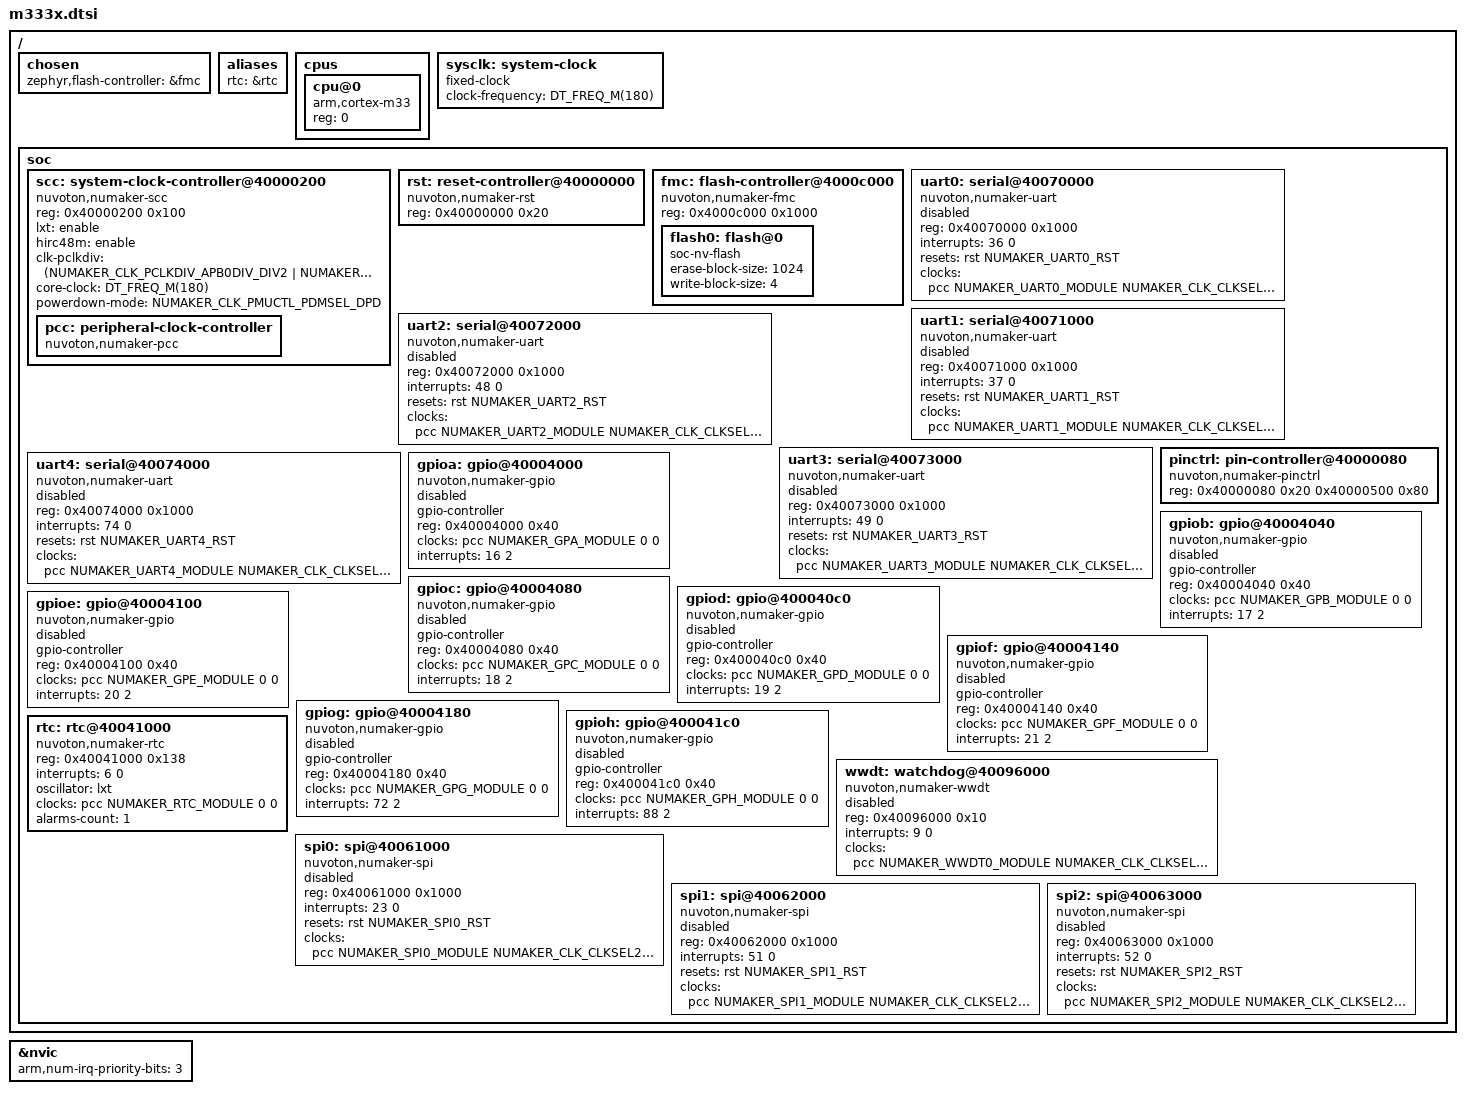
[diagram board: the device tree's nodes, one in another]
/*
 * Copyright (c) 2025 Nuvoton Technology Corporation.
 *
 * SPDX-License-Identifier: Apache-2.0
 */

#include <arm/armv8-m.dtsi>
#include <mem.h>
#include <freq.h>
#include <zephyr/dt-bindings/clock/numaker_m333x_clock.h>
#include <zephyr/dt-bindings/reset/numaker_m333x_reset.h>
#include <zephyr/dt-bindings/gpio/gpio.h>

/ {
	chosen {
		zephyr,flash-controller = &fmc;
	};

	aliases {
		rtc = &rtc;
	};

	cpus {
		#address-cells = <1>;
		#size-cells = <0>;

		cpu@0 {
			device_type = "cpu";
			compatible = "arm,cortex-m33";
			reg = <0>;
		};
	};

	sysclk: system-clock {
		compatible = "fixed-clock";
		clock-frequency = <DT_FREQ_M(180)>;
		#clock-cells = <0>;
	};

	soc {
		scc: system-clock-controller@40000200 {
			compatible = "nuvoton,numaker-scc";
			reg = <0x40000200 0x100>;
			#clock-cells = <0>;
			lxt = "enable";
			hirc48m = "enable";
			clk-pclkdiv = <(NUMAKER_CLK_PCLKDIV_APB0DIV_DIV2 |
				       NUMAKER_CLK_PCLKDIV_APB1DIV_DIV2)>;
			core-clock = <DT_FREQ_M(180)>;
			powerdown-mode = <NUMAKER_CLK_PMUCTL_PDMSEL_DPD>;

			pcc: peripheral-clock-controller {
				compatible = "nuvoton,numaker-pcc";
				#clock-cells = <3>;
			};
		};

		rst: reset-controller@40000000 {
			compatible = "nuvoton,numaker-rst";
			reg = <0x40000000 0x20>;
			#reset-cells = <1>;
		};

		fmc: flash-controller@4000c000 {
			compatible = "nuvoton,numaker-fmc";
			reg = <0x4000c000 0x1000>;
			#address-cells = <1>;
			#size-cells = <1>;

			flash0: flash@0 {
				compatible = "soc-nv-flash";
				erase-block-size = <1024>;
				write-block-size = <4>;
			};
		};

		uart0: serial@40070000 {
			compatible = "nuvoton,numaker-uart";
			reg = <0x40070000 0x1000>;
			interrupts = <36 0>;
			resets = <&rst NUMAKER_UART0_RST>;
			clocks = <&pcc NUMAKER_UART0_MODULE NUMAKER_CLK_CLKSEL1_UART0SEL_HIRC
				  NUMAKER_CLK_CLKDIV0_UART0(1)>;
			status = "disabled";
		};

		uart1: serial@40071000 {
			compatible = "nuvoton,numaker-uart";
			reg = <0x40071000 0x1000>;
			interrupts = <37 0>;
			resets = <&rst NUMAKER_UART1_RST>;
			clocks = <&pcc NUMAKER_UART1_MODULE NUMAKER_CLK_CLKSEL1_UART1SEL_HIRC
				  NUMAKER_CLK_CLKDIV0_UART1(1)>;
			status = "disabled";
		};

		uart2: serial@40072000 {
			compatible = "nuvoton,numaker-uart";
			reg = <0x40072000 0x1000>;
			interrupts = <48 0>;
			resets = <&rst NUMAKER_UART2_RST>;
			clocks = <&pcc NUMAKER_UART2_MODULE NUMAKER_CLK_CLKSEL3_UART2SEL_HIRC
				  NUMAKER_CLK_CLKDIV1_UART2(1)>;
			status = "disabled";
		};

		uart3: serial@40073000 {
			compatible = "nuvoton,numaker-uart";
			reg = <0x40073000 0x1000>;
			interrupts = <49 0>;
			resets = <&rst NUMAKER_UART3_RST>;
			clocks = <&pcc NUMAKER_UART3_MODULE NUMAKER_CLK_CLKSEL3_UART3SEL_HIRC
				  NUMAKER_CLK_CLKDIV1_UART3(1)>;
			status = "disabled";
		};

		uart4: serial@40074000 {
			compatible = "nuvoton,numaker-uart";
			reg = <0x40074000 0x1000>;
			interrupts = <74 0>;
			resets = <&rst NUMAKER_UART4_RST>;
			clocks = <&pcc NUMAKER_UART4_MODULE NUMAKER_CLK_CLKSEL3_UART4SEL_HIRC
				  NUMAKER_CLK_CLKDIV1_UART4(1)>;
			status = "disabled";
		};

		pinctrl: pin-controller@40000080 {
			compatible = "nuvoton,numaker-pinctrl";
			reg = <0x40000080 0x20
			       0x40000500 0x80>;
			reg-names = "mfos", "mfp";
		};

		gpioa: gpio@40004000 {
			compatible = "nuvoton,numaker-gpio";
			gpio-controller;
			#gpio-cells = <2>;
			reg = <0x40004000 0x40>;
			clocks = <&pcc NUMAKER_GPA_MODULE 0 0>;
			status = "disabled";
			interrupts = <16 2>;
		};

		gpiob: gpio@40004040 {
			compatible = "nuvoton,numaker-gpio";
			gpio-controller;
			#gpio-cells = <2>;
			reg = <0x40004040 0x40>;
			clocks = <&pcc NUMAKER_GPB_MODULE 0 0>;
			status = "disabled";
			interrupts = <17 2>;
		};

		gpioc: gpio@40004080 {
			compatible = "nuvoton,numaker-gpio";
			gpio-controller;
			#gpio-cells = <2>;
			reg = <0x40004080 0x40>;
			clocks = <&pcc NUMAKER_GPC_MODULE 0 0>;
			status = "disabled";
			interrupts = <18 2>;
		};

		gpiod: gpio@400040c0 {
			compatible = "nuvoton,numaker-gpio";
			gpio-controller;
			#gpio-cells = <2>;
			reg = <0x400040c0 0x40>;
			clocks = <&pcc NUMAKER_GPD_MODULE 0 0>;
			status = "disabled";
			interrupts = <19 2>;
		};

		gpioe: gpio@40004100 {
			compatible = "nuvoton,numaker-gpio";
			gpio-controller;
			#gpio-cells = <2>;
			reg = <0x40004100 0x40>;
			clocks = <&pcc NUMAKER_GPE_MODULE 0 0>;
			status = "disabled";
			interrupts = <20 2>;
		};

		gpiof: gpio@40004140 {
			compatible = "nuvoton,numaker-gpio";
			gpio-controller;
			#gpio-cells = <2>;
			reg = <0x40004140 0x40>;
			clocks = <&pcc NUMAKER_GPF_MODULE 0 0>;
			status = "disabled";
			interrupts = <21 2>;
		};

		gpiog: gpio@40004180 {
			compatible = "nuvoton,numaker-gpio";
			gpio-controller;
			#gpio-cells = <2>;
			reg = <0x40004180 0x40>;
			clocks = <&pcc NUMAKER_GPG_MODULE 0 0>;
			status = "disabled";
			interrupts = <72 2>;
		};

		gpioh: gpio@400041c0 {
			compatible = "nuvoton,numaker-gpio";
			gpio-controller;
			#gpio-cells = <2>;
			reg = <0x400041c0 0x40>;
			clocks = <&pcc NUMAKER_GPH_MODULE 0 0>;
			status = "disabled";
			interrupts = <88 2>;
		};

		rtc: rtc@40041000 {
			compatible = "nuvoton,numaker-rtc";
			reg = <0x40041000 0x138>;
			interrupts = <6 0>;
			oscillator = "lxt";
			clocks = <&pcc NUMAKER_RTC_MODULE 0 0>;
			alarms-count = <1>;
		};

		wwdt: watchdog@40096000 {
			compatible = "nuvoton,numaker-wwdt";
			reg = <0x40096000 0x10>;
			interrupts = <9 0>;
			clocks = <&pcc NUMAKER_WWDT0_MODULE NUMAKER_CLK_CLKSEL1_WWDT0SEL_LIRC 0>;
			status = "disabled";
		};

		spi0: spi@40061000 {
			compatible = "nuvoton,numaker-spi";
			reg = <0x40061000 0x1000>;
			interrupts = <23 0>;
			resets = <&rst NUMAKER_SPI0_RST>;
			clocks = <&pcc NUMAKER_SPI0_MODULE NUMAKER_CLK_CLKSEL2_SPI0SEL_HIRC 0>;
			#address-cells = <1>;
			#size-cells = <0>;
			status = "disabled";
		};

		spi1: spi@40062000 {
			compatible = "nuvoton,numaker-spi";
			reg = <0x40062000 0x1000>;
			interrupts = <51 0>;
			resets = <&rst NUMAKER_SPI1_RST>;
			clocks = <&pcc NUMAKER_SPI1_MODULE NUMAKER_CLK_CLKSEL2_SPI1SEL_HIRC 0>;
			#address-cells = <1>;
			#size-cells = <0>;
			status = "disabled";
		};

		spi2: spi@40063000 {
			compatible = "nuvoton,numaker-spi";
			reg = <0x40063000 0x1000>;
			interrupts = <52 0>;
			resets = <&rst NUMAKER_SPI2_RST>;
			clocks = <&pcc NUMAKER_SPI2_MODULE NUMAKER_CLK_CLKSEL2_SPI2SEL_HIRC 0>;
			#address-cells = <1>;
			#size-cells = <0>;
			status = "disabled";
		};
	};
};

&nvic {
	arm,num-irq-priority-bits = <3>;
};
